# ISD9100_v3 register map
File version: 1.0
Registers are 32-bit, read-write, reset 0x0 unless marked. A register's access mark holds for its fields unless they carry their own. Offsets are from the block's base; [hi:lo] are bit positions; 'fields as' and 'values as' point back to an identical list.

## FMC — FMC Register Map
Base 0x5000C000
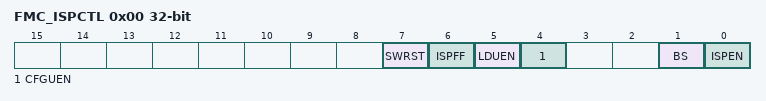
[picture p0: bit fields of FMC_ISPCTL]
0x00 FMC_ISPCTL — ISP Control Register
  [7] SWRST — Software Reset. Writing 1 to this bit will initiate a software reset. It is cleared by hardware after reset.
  [6] ISPFF — ISP Fail Flag. This bit is set by hardware when a triggered ISP meets any of the following conditions: (1) APROM writes to itself. (2) LDROM writes to itself. (3) Destination address is illegal, such as over an available range. Write 1 to clear.
  [5] LDUEN — LDROM Update Enable. LDROM update enable bit.
    0=LDROM cannot be updated; 1=LDROM can be updated when the MCU runs in APROM
  [4] CFGUEN — CONFIG Update Enable. When enabled, ISP functions can access the CONFIG address space and modify device configuration area.
    0=Disable; 1=Enable
  [1] BS — Boot Select. Modify this bit to select which ROM next boot is to occur. This bit also functions as MCU boot status flag, which can be used to check where MCU booted from. This bit is initialized after power-on reset with the inverse of CBS in Config0; It is not reset for any other reset event.
    0=APROM; 1=LDROM
  [0] ISPEN — ISP Enable
    0=Disable ISP function; 1=Enable ISP function
0x04 FMC_ISPADDR — ISP Address Register
  [31:0] ISPADDR — ISP Address Register. This is the memory address register that a subsequent ISP command will access. ISP operation are carried out on 32bit words only, consequently ISPARD[1:0] must be 00b for correct ISP operation.
0x08 FMC_ISPDAT — ISP Data Register
  [31:0] ISPDAT — ISP Data Register. Write data to this register before an ISP program operation. Read data from this register after an ISP read operation
0x0C FMC_ISPCMD — ISP Command Register
  [5:0] CMD — ISP Command. Operation Mode : CMD. Standby : 0x3X. Read : 0x00. Program : 0x21. Page Erase : 0x22. Read CID : 0x0B. Read DID : 0x0C
0x10 FMC_ISPTRG — ISP Trigger Control Register
  [0] ISPGO — ISP Start Trigger. Write 1 to start ISP operation. This will be cleared to 0 by hardware automatically when ISP operation is finished. After triggering an ISP function M0 instruction pipeline should be flushed with a ISB instruction to guarantee data integrity. This is a protected register, user must first follow the unlock sequence (see Protected Register Lock Key Register (SYS_REGLCTL)) to gain access.
    0=ISP operation is finished; 1=ISP is on going
0x14 FMC_DFBA ro reset not defined — Data Flash Base Address
  [31:0] DFBA — Data Flash Base Address. This register reports the data flash starting address. It is a read only register. Data flash size is defined by user's configuration; register content is loaded from Config1 when chip is reset.

## ADC — ADC Register Map
Base 0x400E0000
0x00 ADC_DAT ro (reset mask 0xFFFF0000) — ADC FIFO Data Out.
  [15:0] RESULT — ADC Audio Data FIFO Read. A read of this register will read data from the audio FIFO and increment the read pointer. A read past empty will repeat the last data. Can be used with FIFOINTLV interrupt to determine if valid data is present in FIFO.
0x04 ADC_CHEN — ADC Enable Register
  [0] CHEN — ADC Enable
    0=Conversion stopped and ADC is reset including FIFO pointers; 1=ADC Conversion enabled
0x08 ADC_CLKDIV — ADC Clock Divider Register
  [7:0] CLKDIV — ADC Clock Divider. This register determines the clock division ration between the incoming ADC_CLK (aaa HCLK by default) and the Delta-Sigma sampling clock of the ADC. This together with the over-sampling ratio (OSR) determines the audio sample rate of the converter. CLKDIV should be set to give a SD_CLK frequency in the range of 1.024-6.144MHz. CLKDIV must be greater than 2. SD_CLK frequency aaa HCLK / CLKDIV
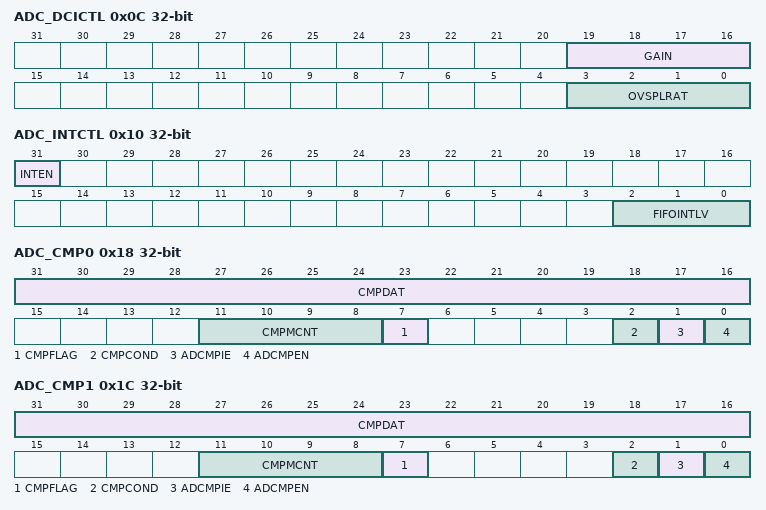
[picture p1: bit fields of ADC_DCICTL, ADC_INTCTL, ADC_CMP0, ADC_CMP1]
0x0C ADC_DCICTL — ADC Decimation Control Register
  [19:16] GAIN — CIC Filter Additional Gain. This should normally remain default 0. Can be set to non-zero values to provide additional digital gain from the decimation filter. An additional gain is applied to signal of GAIN/2.
  [3:0] OVSPLRAT — Decimation Over-Sampling Ratio. This term determines the over-sampling ratio of the decimation filter. Valid values are: 0: OVSPLRAT aaa 64. 1: OVSPLRAT aaa 128. 2: OVSPLRAT aaa 192. 3: OVSPLRAT aaa 384
0x10 ADC_INTCTL — ADC Interrupt Control Register
  [31] INTEN — Interrupt Enable. If set to '1' an interrupt is generated whenever FIFO level exceeds that set in FIFOINTLV.
  [2:0] FIFOINTLV — FIFO Interrupt Level. Determines at what level the ADC FIFO will generate a servicing interrupt to the CPU. Interrupt will be generated when number of words present in ADC FIFO is > FIFOINTLV.
0x14 ADC_PDMACTL — ADC PDMA Control Register
  [0] RXDMAEN — Enable ADC PDMA Receive Channel. Enable ADC PDMA. If set, then ADC will request PDMA service when data is available.
0x18 ADC_CMP0 — ADC Comparator 0 Control Register
  [31:16] CMPDAT — Comparison Data. 16 bit value to compare to FIFO output word.
  [11:8] CMPMCNT — Compare Match Count. When the A/D FIFO result matches the compare condition defined by CMPCOND, the internal match counter will increase by 1. When the internal counter reaches the value to (CMPMCNT +1), the CMPFLAG bit will be set.
  [7] CMPFLAG — Compare Flag. When the conversion result meets condition in ADCMPR0 this bit is set to 1. It is cleared by writing 1 to self.
  [2] CMPCOND — Compare Condition. Note: When the internal counter reaches the value (CMPMCNT +1), the CMPFLAG bit will be set.
    0=Set the compare condition that result is less than CMPDAT; 1=Set the compare condition that result is greater or equal to CMPDAT
  [1] ADCMPIE — Compare Interrupt Enable. If the compare function is enabled and the compare condition matches the setting of CMPCOND and CMPMCNT, CMPFLAG bit will be asserted, if ADCMPIE is set to 1, a compare interrupt request is generated.
    0=Disable compare function interrupt; 1=Enable compare function interrupt
  [0] ADCMPEN — Compare Enable. Set this bit to 1 to enable compare CMPDAT with FIFO data output.
    0=Disable compare; 1=Enable compare
0x1C ADC_CMP1 — ADC Comparator 1 Control Register
  fields as ADC_CMP0
